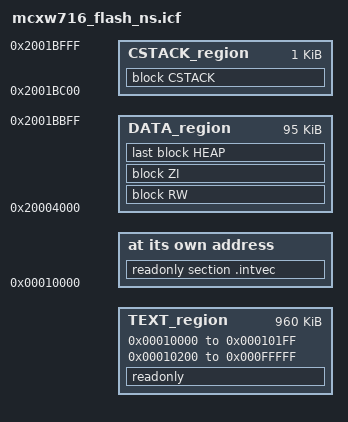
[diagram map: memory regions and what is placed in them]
/*
** ###################################################################
**     Processors:          KW45B41Z83AFPA
**                          KW45B41Z83AFTA
**
**     Compiler:            IAR ANSI C/C++ Compiler for ARM
**     Reference manual:    KW45B41, Rev. 0 Draft F, July 2020
**     Version:             rev. 1.0, 2020-05-12
**     Build:               b210423
**
**     Abstract:
**         Linker file for the IAR ANSI C/C++ Compiler for ARM
**
**     Copyright 2016 Freescale Semiconductor, Inc.
**     Copyright 2016-2021 NXP
**     All rights reserved.
**
**     SPDX-License-Identifier: BSD-3-Clause
**
**     http:                 www.nxp.com
**     mail:                 support@nxp.com
**
** ###################################################################
*/


/* Stack and Heap Sizes */
if (isdefinedsymbol(__stack_size__)) {
  define symbol __size_cstack__        = __stack_size__;
} else {
  define symbol __size_cstack__        = 0x0400;
}

if (isdefinedsymbol(__heap_size__)) {
  define symbol __size_heap__          = __heap_size__;
} else {
  define symbol __size_heap__          = 0x0400;
}

define symbol m_interrupts_start               = 0x00010000;
define symbol m_interrupts_end                 = 0x000101FF;

define symbol m_text_start                     = 0x00010200;
define symbol m_text_end                       = 0x000FFFFF;


define symbol m_data1_start                     = 0x20004000;
define symbol m_data1_end                       = 0x2001BFFF - __size_cstack__;

define symbol m_stack_start                    = 0x2001C000 - __size_cstack__;
define symbol m_stack_end                      = 0x2001BFFF;

define memory mem with size = 4G;

define region TEXT_region             = mem:[from m_interrupts_start to m_interrupts_end]
                                      | mem:[from m_text_start to m_text_end];
define region DATA_region             = mem:[from m_data1_start to m_data1_end];
define region CSTACK_region           = mem:[from m_stack_start to m_stack_end];

define block CSTACK    with alignment = 8, size = __size_cstack__   { };
define block HEAP      with alignment = 8, size = __size_heap__     { };
define block RW        { readwrite };
define block ZI        { zi };

initialize by copy { readwrite, section .textrw };

if (isdefinedsymbol(__USE_DLIB_PERTHREAD))
{
  /* Required in a multi-threaded application */
  initialize by copy with packing = none { section __DLIB_PERTHREAD };
}

do not initialize  { section .noinit };

place at address mem: m_interrupts_start    { readonly section .intvec };
place in TEXT_region                        { readonly };
place in DATA_region                        { block RW };
place in DATA_region                        { block ZI };
place in DATA_region                        { last block HEAP };
place in CSTACK_region                      { block CSTACK };
